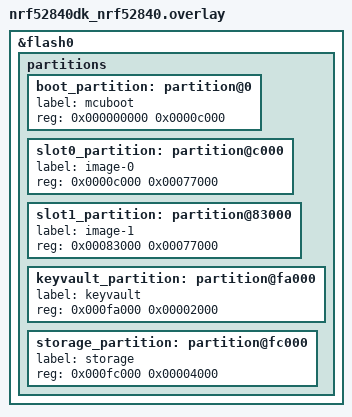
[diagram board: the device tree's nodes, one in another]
/delete-node/ &boot_partition;
/delete-node/ &slot0_partition;
/delete-node/ &slot1_partition;
/delete-node/ &scratch_partition;

&flash0 {

	partitions {

		/**
		* @desc The bootloader partition containing MCUboot
		* @size 48kb
		*/
		boot_partition: partition@0 {
			label = "mcuboot";
			reg = <0x000000000 0x0000c000>;
		};

		/**
		* @desc Image the system boots from.
		* @size 392kb
		*/
		slot0_partition: partition@c000 {
			label = "image-0";
			reg = <0x0000c000 0x00077000>;
		};

		/**
		* @desc Image swapped to slot 0 at bootup by MCUboot
		* @size 392kb
		*/
		slot1_partition: partition@83000 {
			label = "image-1";
			reg = <0x00083000 0x00077000>;
		};

		/**
		* @desc Keyvault for provisioned secrets and configuration data. this one is used.
		* @size 24kb
		*/
		keyvault_partition: partition@fa000 {
			label = "keyvault";
			reg = <0x000fa000 0x00002000>;
		};

		/**
		* @desc Image for firmware updates.
		* @size 16kb
		*/
		storage_partition: partition@fc000 {
			label = "storage";
			reg = <0x000fc000 0x00004000>;
		};
	};
};
